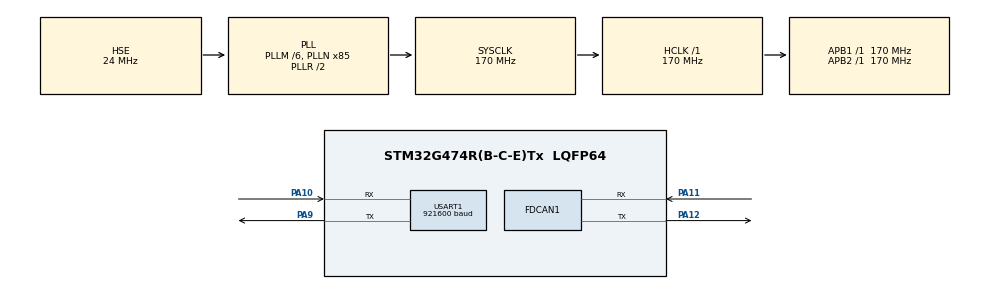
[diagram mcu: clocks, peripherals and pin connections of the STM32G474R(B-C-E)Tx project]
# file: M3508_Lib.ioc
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Dma.Request0=USART1_RX
Dma.Request1=USART1_TX
Dma.USART1_RX.0.Direction=DMA_PERIPH_TO_MEMORY
Dma.USART1_RX.0.EventEnable=DISABLE
Dma.USART1_RX.0.Instance=DMA1_Channel1
Dma.USART1_RX.0.MemDataAlignment=DMA_MDATAALIGN_BYTE
Dma.USART1_RX.0.MemInc=DMA_MINC_ENABLE
Dma.USART1_RX.0.Mode=DMA_CIRCULAR
Dma.USART1_RX.0.PeriphDataAlignment=DMA_PDATAALIGN_BYTE
Dma.USART1_RX.0.PeriphInc=DMA_PINC_DISABLE
Dma.USART1_RX.0.Polarity=HAL_DMAMUX_REQ_GEN_RISING
Dma.USART1_RX.0.Priority=DMA_PRIORITY_HIGH
Dma.USART1_RX.0.RequestNumber=1
Dma.USART1_RX.0.SignalID=NONE
Dma.USART1_RX.0.SyncEnable=DISABLE
Dma.USART1_RX.0.SyncPolarity=HAL_DMAMUX_SYNC_NO_EVENT
Dma.USART1_RX.0.SyncRequestNumber=1
Dma.USART1_RX.0.SyncSignalID=NONE
Dma.USART1_TX.1.Direction=DMA_MEMORY_TO_PERIPH
Dma.USART1_TX.1.EventEnable=DISABLE
Dma.USART1_TX.1.Instance=DMA1_Channel2
Dma.USART1_TX.1.MemDataAlignment=DMA_MDATAALIGN_BYTE
Dma.USART1_TX.1.MemInc=DMA_MINC_ENABLE
Dma.USART1_TX.1.Mode=DMA_NORMAL
Dma.USART1_TX.1.PeriphDataAlignment=DMA_PDATAALIGN_BYTE
Dma.USART1_TX.1.PeriphInc=DMA_PINC_DISABLE
Dma.USART1_TX.1.Polarity=HAL_DMAMUX_REQ_GEN_RISING
Dma.USART1_TX.1.Priority=DMA_PRIORITY_MEDIUM
Dma.USART1_TX.1.RequestNumber=1
Dma.USART1_TX.1.SignalID=NONE
Dma.USART1_TX.1.SyncEnable=DISABLE
Dma.USART1_TX.1.SyncPolarity=HAL_DMAMUX_SYNC_NO_EVENT
Dma.USART1_TX.1.SyncRequestNumber=1
Dma.USART1_TX.1.SyncSignalID=NONE
FDCAN1.AutoRetransmission=ENABLE
FDCAN1.CalculateBaudRateNominal=999999
FDCAN1.CalculateTimeBitNominal=1000
FDCAN1.CalculateTimeQuantumNominal=58.82352941176471
FDCAN1.NominalPrescaler=10
FDCAN1.NominalSyncJumpWidth=3
FDCAN1.NominalTimeSeg1=13
FDCAN1.NominalTimeSeg2=3
FDCAN1.StdFiltersNbr=1
FREERTOS.Tasks01=defaultTask,24,128,StartDefaultTask,Default,NULL,Dynamic,NULL,NULL
FREERTOS.configCHECK_FOR_STACK_OVERFLOW=2
FREERTOS.configTOTAL_HEAP_SIZE=32768
FREERTOS.configUSE_NEWLIB_REENTRANT=1
Mcu.Family=STM32G4
Mcu.Name=STM32G474R(B-C-E)Tx
Mcu.Package=LQFP64
NUCLEO-G474RE.BUTTON=1
NUCLEO-G474RE.LD2=true
NUCLEO-G474RE.VCP=true
NVIC.DMA1_Channel1_IRQn=true\:6\:0\:true\:false\:true\:true\:false\:true\:true
NVIC.DMA1_Channel2_IRQn=true\:6\:0\:true\:false\:true\:true\:false\:true\:true
NVIC.EXTI15_10_IRQn=true\:5\:0\:false\:false\:true\:true\:false\:true\:true
NVIC.FDCAN1_IT0_IRQn=true\:5\:0\:false\:false\:true\:true\:true\:true\:true
NVIC.PriorityGroup=NVIC_PRIORITYGROUP_4
NVIC.TIM6_DAC_IRQn=true\:15\:0\:false\:false\:true\:false\:false\:true\:true
NVIC.TimeBase=TIM6_DAC_IRQn
NVIC.TimeBaseIP=TIM6
NVIC.USART1_IRQn=true\:6\:0\:true\:false\:true\:true\:true\:true\:true
PA10.Mode=Asynchronous
PA10.Signal=USART1_RX
PA11.Mode=FDCAN_Activate
PA11.Signal=FDCAN1_RX
PA12.Mode=FDCAN_Activate
PA12.Signal=FDCAN1_TX
PA13.GPIO_Label=T_SWDIO
PA13.Mode=Serial_Wire
PA13.Signal=SYS_JTMS-SWDIO
PA14.GPIO_Label=T_SWCLK
PA14.Mode=Serial_Wire
PA14.Signal=SYS_JTCK-SWCLK
PA2.Signal=LPUART1_TX
PA3.Signal=LPUART1_RX
PA9.Mode=Asynchronous
PA9.Signal=USART1_TX
PB3.GPIO_Label=T_SWO
PB3.Signal=SYS_JTDO-SWO
PC14-OSC32_IN.GPIO_Label=RCC_OSC32_IN
PC14-OSC32_IN.Signal=RCC_OSC32_IN
PC15-OSC32_OUT.GPIO_Label=RCC_OSC32_OUT
PC15-OSC32_OUT.Signal=RCC_OSC32_OUT
PF0-OSC_IN.GPIO_Label=RCC_OSC_IN
PF0-OSC_IN.Mode=HSE-External-Oscillator
PF0-OSC_IN.Signal=RCC_OSC_IN
PF1-OSC_OUT.GPIO_Label=RCC_OSC_OUT
PF1-OSC_OUT.Mode=HSE-External-Oscillator
PF1-OSC_OUT.Signal=RCC_OSC_OUT
ProjectManager.HeapSize=0x200
ProjectManager.StackSize=0x400
ProjectManager.TargetToolchain=CMake
RCC.ADC12Freq_Value=170000000
RCC.ADC345Freq_Value=170000000
RCC.AHBFreq_Value=170000000
RCC.APB1Freq_Value=170000000
RCC.APB1TimFreq_Value=170000000
RCC.APB2Freq_Value=170000000
RCC.APB2TimFreq_Value=170000000
RCC.CortexFreq_Value=170000000
RCC.EXTERNAL_CLOCK_VALUE=12288000
RCC.HCLKFreq_Value=170000000
RCC.HSE_VALUE=24000000
RCC.HSI48_VALUE=48000000
RCC.HSI_VALUE=16000000
RCC.LSE_VALUE=32768
RCC.PLLM=RCC_PLLM_DIV6
RCC.PLLN=85
RCC.PLLSourceVirtual=RCC_PLLSOURCE_HSE
RCC.RTCClockSelection=RCC_RTCCLKSOURCE_LSE
RCC.SYSCLKFreq_VALUE=170000000
RCC.SYSCLKSource=RCC_SYSCLKSOURCE_PLLCLK
RCC.USBFreq_Value=170000000
RCC.VCOOutputFreq_Value=340000000
USART1.BaudRate=921600
USART1.VirtualMode-Asynchronous=VM_ASYNC
VP_FREERTOS_VS_CMSIS_V2.Mode=CMSIS_V2
VP_NUCLEO-G474RE_VS_BSP_COMMON.Mode=COMMON
VP_SYS_VS_DBSignals.Mode=DisableDeadBatterySignals
VP_SYS_VS_tim6.Mode=TIM6
board=NUCLEO-G474RE

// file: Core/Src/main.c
/* USER CODE BEGIN Header */
/**
  ******************************************************************************
  * @file           : main.c
  * @brief          : Main program body
  ******************************************************************************
  * @attention
  *
  * Copyright (c) 2026 STMicroelectronics.
  * All rights reserved.
  *
  * This software is licensed under terms that can be found in the LICENSE file
  * in the root directory of this software component.
  * If no LICENSE file comes with this software, it is provided AS-IS.
  *
  ******************************************************************************
  */
/* USER CODE END Header */
#include "main.h"
#include "cmsis_os.h"
#include "dma.h"
#include "fdcan.h"
#include "usart.h"
#include "gpio.h"

COM_InitTypeDef BspCOMInit;

void SystemClock_Config(void);
void MX_FREERTOS_Init(void);

int main(void)
{

  /* MCU Configuration--------------------------------------------------------*/

  /* Reset of all peripherals, Initializes the Flash interface and the Systick. */
  HAL_Init();

  /* Configure the system clock */
  SystemClock_Config();

  /* Initialize all configured peripherals */
  MX_GPIO_Init();
  MX_DMA_Init();
  MX_FDCAN1_Init();
  MX_USART1_UART_Init();

  /* Init scheduler */
  osKernelInitialize();  /* Call init function for freertos objects (in cmsis_os2.c) */
  MX_FREERTOS_Init();

  /* Initialize led */
  BSP_LED_Init(LED_GREEN);

  /* Initialize USER push-button, will be used to trigger an interrupt each time it's pressed.*/
  BSP_PB_Init(BUTTON_USER, BUTTON_MODE_EXTI);

  /* Initialize COM1 port (115200, 8 bits (7-bit data + 1 stop bit), no parity */
  BspCOMInit.BaudRate   = 115200;
  BspCOMInit.WordLength = COM_WORDLENGTH_8B;
  BspCOMInit.StopBits   = COM_STOPBITS_1;
  BspCOMInit.Parity     = COM_PARITY_NONE;
  BspCOMInit.HwFlowCtl  = COM_HWCONTROL_NONE;
  if (BSP_COM_Init(COM1, &BspCOMInit) != BSP_ERROR_NONE)
  {
    Error_Handler();
  }

  /* Start scheduler */
  osKernelStart();

  /* We should never get here as control is now taken by the scheduler */

  /* Infinite loop */
  while (1)
  {

  }
}

void SystemClock_Config(void)
{
  RCC_OscInitTypeDef RCC_OscInitStruct = {0};
  RCC_ClkInitTypeDef RCC_ClkInitStruct = {0};

  /** Configure the main internal regulator output voltage
  */
  HAL_PWREx_ControlVoltageScaling(PWR_REGULATOR_VOLTAGE_SCALE1_BOOST);

  /** Initializes the RCC Oscillators according to the specified parameters
  * in the RCC_OscInitTypeDef structure.
  */
  RCC_OscInitStruct.OscillatorType = RCC_OSCILLATORTYPE_HSE;
  RCC_OscInitStruct.HSEState = RCC_HSE_ON;
  RCC_OscInitStruct.PLL.PLLState = RCC_PLL_ON;
  RCC_OscInitStruct.PLL.PLLSource = RCC_PLLSOURCE_HSE;
  RCC_OscInitStruct.PLL.PLLM = RCC_PLLM_DIV6;
  RCC_OscInitStruct.PLL.PLLN = 85;
  RCC_OscInitStruct.PLL.PLLP = RCC_PLLP_DIV2;
  RCC_OscInitStruct.PLL.PLLQ = RCC_PLLQ_DIV2;
  RCC_OscInitStruct.PLL.PLLR = RCC_PLLR_DIV2;
  if (HAL_RCC_OscConfig(&RCC_OscInitStruct) != HAL_OK)
  {
    Error_Handler();
  }

  /** Initializes the CPU, AHB and APB buses clocks
  */
  RCC_ClkInitStruct.ClockType = RCC_CLOCKTYPE_HCLK|RCC_CLOCKTYPE_SYSCLK
                              |RCC_CLOCKTYPE_PCLK1|RCC_CLOCKTYPE_PCLK2;
  RCC_ClkInitStruct.SYSCLKSource = RCC_SYSCLKSOURCE_PLLCLK;
  RCC_ClkInitStruct.AHBCLKDivider = RCC_SYSCLK_DIV1;
  RCC_ClkInitStruct.APB1CLKDivider = RCC_HCLK_DIV1;
  RCC_ClkInitStruct.APB2CLKDivider = RCC_HCLK_DIV1;

  if (HAL_RCC_ClockConfig(&RCC_ClkInitStruct, FLASH_LATENCY_4) != HAL_OK)
  {
    Error_Handler();
  }
}

void HAL_TIM_PeriodElapsedCallback(TIM_HandleTypeDef *htim)
{
  if (htim->Instance == TIM6)
  {
    HAL_IncTick();
  }
}

void Error_Handler(void)
{
  __disable_irq();
  while (1)
  {
  }
}

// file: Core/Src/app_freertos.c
/* USER CODE BEGIN Header */
/**
  ******************************************************************************
  * File Name          : app_freertos.c
  * Description        : Code for freertos applications
  ******************************************************************************
  * @attention
  *
  * Copyright (c) 2026 STMicroelectronics.
  * All rights reserved.
  *
  * This software is licensed under terms that can be found in the LICENSE file
  * in the root directory of this software component.
  * If no LICENSE file comes with this software, it is provided AS-IS.
  *
  ******************************************************************************
  */
/* USER CODE END Header */

#include "FreeRTOS.h"
#include "task.h"
#include "main.h"
#include "cmsis_os.h"

/* USER CODE BEGIN Includes */
#include "app_tasks.h"
#include "chassis.h"

/* USER CODE END Includes */

/* Definitions for defaultTask */
osThreadId_t defaultTaskHandle;
const osThreadAttr_t defaultTask_attributes = {
  .name = "defaultTask",
  .priority = (osPriority_t) osPriorityNormal,
  .stack_size = 128 * 4
};

void StartDefaultTask(void *argument);

void MX_FREERTOS_Init(void); /* (MISRA C 2004 rule 8.1) */

/* Hook prototypes */
void vApplicationStackOverflowHook(xTaskHandle xTask, signed char *pcTaskName);

/* USER CODE BEGIN 4 */
void vApplicationStackOverflowHook(xTaskHandle xTask, signed char *pcTaskName)
{
   /* Run time stack overflow checking is performed if
   configCHECK_FOR_STACK_OVERFLOW is defined to 1 or 2. This hook function is
   called if a stack overflow is detected. */
   (void)xTask;
   (void)pcTaskName;          /* inspect in the debugger to see which task overflowed */
   taskDISABLE_INTERRUPTS();
   for (;;) { }               /* halt here instead of running on with a corrupted stack */
}
/* USER CODE END 4 */

void MX_FREERTOS_Init(void) {

  /* Create the thread(s) */
  /* creation of defaultTask */
  defaultTaskHandle = osThreadNew(StartDefaultTask, NULL, &defaultTask_attributes);

  /* USER CODE BEGIN RTOS_THREADS */
  /* add threads, ... */
  app_tasks_create();        /* inputTask, processTask, outputTask - see app_tasks.h */
  /* USER CODE END RTOS_THREADS */

}

void StartDefaultTask(void *argument)
{
  /* USER CODE BEGIN StartDefaultTask */
  /* Status LED only (lowest priority, does no control work):
       slow blink (1 Hz)  = driving normally
       fast blink (5 Hz)  = not driving: no command yet, command link lost, or a motor offline */
  for(;;)
  {
    chassis_state_t st;
    chassis_get_state(&st);
    BSP_LED_Toggle(LED_GREEN);
    osDelay(st.mode == CHASSIS_DRIVE ? 500 : 100);
  }
  /* USER CODE END StartDefaultTask */
}
